# N575F145_v1 register map
File version: 1.0
Registers are 32-bit, read-write, reset 0x0 unless marked. A register's access mark holds for its fields unless they carry their own. Offsets are from the block's base; [hi:lo] are bit positions.

## UART0 — UART0 Register Map
Base 0x40050000
0x00 DATA reset not defined — UART0 Receive/Transfer FIFO Register.
  [7:0] _8_bitReceivedData — Receive FIFO Register. Reading this register will return data from the receive data FIFO. By reading this register, the UART will return the 8-bit data received from Rx pin (LSB first).
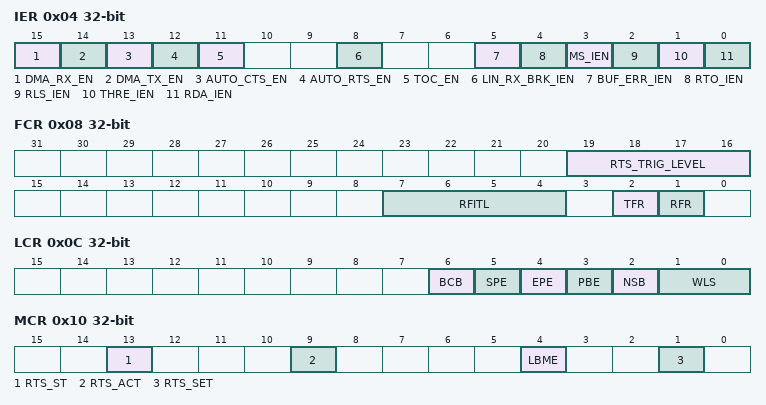
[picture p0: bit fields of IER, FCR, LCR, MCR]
0x04 IER — UART0 Interrupt Enable Register.
  [15] DMA_RX_EN — Receive DMA Enable. If enabled, the UART will request DMA service when data is available in receive FIFO.
  [14] DMA_TX_EN — Transmit DMA Enable. If enabled, the UART will request DMA service when space is available in transmit FIFO.
  [13] AUTO_CTS_EN — CTS Auto Flow Control Enable. When CTS auto-flow is enabled, the UART will send data to external device when CTS input is asserted (UART will not send data to device until CTS is asserted).
    0=Disable CTS auto flow control; 1=Enable
  [12] AUTO_RTS_EN — RTS Auto Flow Control Enable. When RTS auto-flow is enabled, if the number of bytes in the Rx FIFO equals FCR.RTS_TRIG_LEVEL, the UART will de-assert the RTS signal.
    0=Disable RTS auto flow control; 1=Enable
  [11] TOC_EN — Time-Out Counter Enable
    0=Disable Time-out counter; 1=Enable
  [8] LIN_RX_BRK_IEN — LIN RX Break Field Detected Interrupt Enable
    0=Mask off Lin bus Rx break field interrupt; 1=Enable Lin bus Rx break field interrupt
  [5] BUF_ERR_IEN — Buffer Error Interrupt Enable
    0=Mask off BUF_ERR_INT; 1=Enable IBUF_ERR_INT
  [4] RTO_IEN — Receive Time out Interrupt Enable
    0=Mask off TOUT_INT; 1=Enable TOUT_INT
  [3] MS_IEN — Modem Status Interrupt Enable
    0=Mask off MODEM_INT; 1=Enable MODEM_INT
  [2] RLS_IEN — Receive Line Status Interrupt Enable
    0=Mask off RLS_INT; 1=Enable RLS_INT
  [1] THRE_IEN — Transmit FIFO Register Empty Interrupt Enable
    0=Mask off THRE_INT; 1=Enable THRE_INT
  [0] RDA_IEN — Receive Data Available Interrupt Enable.
    0=Mask off RDA_INT; 1=Enable RDA_INT
0x08 FCR — UART0 FIFO Control Register.
  [19:16] RTS_TRIG_LEVEL — RTS Trigger Level for Auto-flow Control. Sets the FIFO trigger level when auto-flow control will de-assert RTS (request-to-send). Value : Trigger Level (Bytes). 0 : 1. 1 : 4. 2 : 8
  [7:4] RFITL — Receive FIFO Interrupt (RDA_INT) Trigger Level. When the number of bytes in the receive FIFO equals the RFITL then the RDA_IF will be set and, if enabled, an RDA_INT interrupt will generated. Value : INTR_RDA Trigger Level (Bytes). 0 : 1. 1 : 4. 2 : 8
  [2] TFR — Transmit FIFO Reset. When TFR is set, all the bytes in the transmit FIFO are cleared and transmit internal state machine is reset. Note: This bit will auto-clear after 3 UART engine clock cycles.
    0=Writing 0 to this bit has no effect; 1=Writing 1 to this bit will reset the transmit internal state machine and pointers
  [1] RFR — Receive FIFO Reset. When RFR is set, all the bytes in the receive FIFO are cleared and receive internal state machine is reset. Note: This bit will auto-clear after 3 UART engine clock cycles.
    0=Writing 0 to this bit has no effect; 1=Writing 1 to this bit will reset the receive internal state machine and pointers
0x0C LCR — UART0 Line Control Register.
  [6] BCB — Break Control Bit. When this bit is set to logic 1, the serial data output (Tx) is forced to the 'Space' state (logic 0). Normal condition is serial data output is 'Mark' state. This bit acts only on Tx and has no effect on the transmitter logic.
  [5] SPE — Stick Parity Enable
    0=Disable stick parity; 1=When bits PBE and SPE are set 'Stick Parity' is enabled. If EPE=0 the parity bit is transmitted and checked as always set, if EPE=1, the parity bit is transmitted and checked as always cleared
  [4] EPE — Even Parity Enable. This bit has effect only when PBE (parity bit enable) is set.
    0=Odd number of logic 1's are transmitted or checked in the data word and parity bits; 1=Even number of logic 1's are transmitted or checked in the data word and parity bits
  [3] PBE — Parity Bit Enable
    0=Parity bit is not generated (transmit data) or checked (receive data) during transfer; 1=Parity bit is generated or checked between the "last data word bit" and "stop bit" of the serial data
  [2] NSB — Number of STOP bits
    0=One "STOP bit" is generated after the transmitted data; 1=Two "STOP bits" are generated when 6-, 7- and 8-bit word length is selected; One and a half "STOP bits" are generated in the transmitted data when 5-bit word length is selected;
  [1:0] WLS — Word Length Select. 0 (5bits), 1(6bits), 2(7bits), 3(8bits)
0x10 MCR — UART0 Modem Control Register.
  [13] RTS_ST ro — RTS Pin State (read only). This bit is the pin status of RTS.
  [9] RTS_ACT — Request-to-Send (RTS) Active Trigger Level. This bit can change the RTS trigger level.
    0=RTS is active low level; 1=RTS is active high level
  [4] LBME — Loopback Mode Enable
    0=Disable; 1=Enable
  [1] RTS_SET — RTS (Request-To-Send) Signal. If IER.AUTO_RTS_EN = 0, this bit controls whether RTS pin is active or not.
    0=Drive RTS inactive ( = ~RTS_ACT); 1=Drive RTS active ( = RTS_ACT)
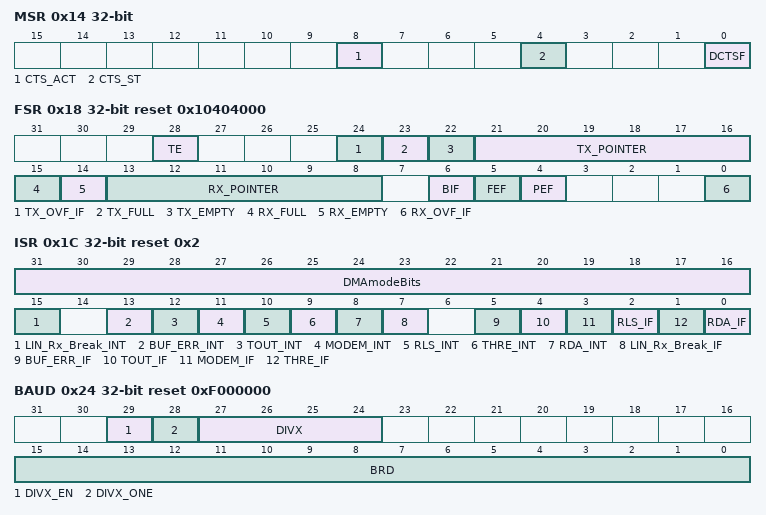
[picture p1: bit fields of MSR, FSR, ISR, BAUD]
0x14 MSR — UART0 Modem Status Register.
  [8] CTS_ACT — Clear-to-Send (CTS) Active Trigger Level. This bit can change the CTS trigger level.
    0=CTS is active low level; 1=CTS is active high level
  [4] CTS_ST ro — CTS Pin Status (read only). This bit is the pin status of CTS.
  [0] DCTSF — Detect CTS State Change Flag. This bit is set whenever CTS input has state change. It will generate Modem interrupt to CPU when IER.MS_IEN = 1. NOTE: This bit is cleared by writing 1 to itself.
0x18 FSR reset 0x10404000 — UART0 FIFO Status Register.
  [28] TE ro — Transmitter Empty (Read Only). Bit is set by hardware when Tx FIFO is empty and the STOP bit of the last byte has been transmitted. Bit is cleared automatically when Tx FIFO is not empty or the last byte transmission has not completed. NOTE: This bit is read only.
  [24] TX_OVF_IF — Tx Overflow Error Interrupt Flag. If the Tx FIFO (UART0->DATA) is full, an additional write to UART0->DATA will cause an overflow condition and set this bit to logic 1. It will also generate a BUF_ERR_IF event and interrupt if enabled. NOTE: This bit is cleared by writing 1 to itself.
  [23] TX_FULL ro — Transmit FIFO Full (Read Only). This bit indicates whether the Tx FIFO is full or not.
  [22] TX_EMPTY ro — Transmit FIFO Empty (Read Only). This bit indicates whether the Tx FIFO is empty or not. When the last byte of Tx FIFO has been transferred to Transmitter Shift Register, hardware sets this bit high. It will be cleared after writing data to FIFO (Tx FIFO not empty).
  [21:16] TX_POINTER ro — Tx FIFO Pointer (Read Only). This field returns the Tx FIFO buffer pointer. When CPU writes a byte into the Tx FIFO, TX_POINTER is incremented. When a byte from Tx FIFO is transferred to the Transmit Shift Register, TX_POINTER is decremented.
  [15] RX_FULL ro — Receive FIFO Full (Read Only). This bit indicates whether the Rx FIFO is full or not. This bit is set when Rx FIFO is full; otherwise it is cleared by hardware.
  [14] RX_EMPTY ro — Receive FIFO Empty (Read Only). This bit indicates whether the Rx FIFO is empty or not. When the last byte of Rx FIFO has been read by CPU, hardware sets this bit high. It will be cleared when UART receives any new data.
  [13:8] RX_POINTER ro — Rx FIFO pointer (Read Only). This field returns the Rx FIFO buffer pointer. It is the number of bytes available for read in the Rx FIFO. When UART receives one byte from external device, RX_POINTER is incremented. When one byte of Rx FIFO is read by CPU, RX_POINTER is decremented.
  [6] BIF — Break Interrupt Flag. This bit is set to a logic 1 whenever the receive data input (Rx) is held in the "space" state (logic 0) for longer than a full word transmission time (that is, the total time of start bit + data bits + parity + stop bits). It is reset whenever the CPU writes 1 to this bit.
  [5] FEF — Framing Error Flag. This bit is set to logic 1 whenever the received character does not have a valid "stop bit" (that is, the stop bit following the last data bit or parity bit is detected as a logic 0), and is reset whenever the CPU writes 1 to this bit.
  [4] PEF — Parity Error Flag. This bit is set to logic 1 whenever the received character does not have a valid "parity bit", and is reset whenever the CPU writes 1 to this bit.
  [0] RX_OVF_IF — Rx Overflow Error Interrupt Flag. If the Rx FIFO (UART0->DATA) is full, and an additional byte is received by the UART, an overflow condition will occur and set this bit to logic 1. It will also generate a BUF_ERR_IF event and interrupt if enabled. NOTE: This bit is cleared by writing 1 to itself.
0x1C ISR reset 0x2 — UART0 Interrupt Status Register.
  [31:16] DMAmodeBits — DMA Mode Bits. DMA mode equivalent following interrupt indicators and flags. See Table 5107 and normal mode descriptions below. In DMA mode (either DMA transmit or receive requests are active) these bits are generated rather than the normal use bits below.
  [15] LIN_Rx_Break_INT — LIN Bus Rx Break Field Detected Interrupt Indicator to Interrupt Controller. Logical AND of IER.LIN_RX_BRK_IEN and LIN_Rx_Break_IF.
  [13] BUF_ERR_INT — Buffer Error Interrupt Indicator to Interrupt Controller. Logical AND of IER.BUF_ERR_IEN and BUF_ERR_IF.
  [12] TOUT_INT — Time Out Interrupt Indicator to Interrupt Controller. Logical AND of IER.RTO_IEN and TOUT_IF.
  [11] MODEM_INT — MODEM Status Interrupt Indicator to Interrupt. Logical AND of IER.MS_IEN and MODEM_IF.
  [10] RLS_INT — Receive Line Status Interrupt Indicator to Interrupt Controller. Logical AND of IER.RLS_IEN and RLS_IF.
  [9] THRE_INT — Transmit Holding Register Empty Interrupt Indicator to Interrupt Controller. Logical AND of IER.THRE_IEN and THRE_IF.
  [8] RDA_INT — Receive Data Available Interrupt Indicator to Interrupt Controller. Logical AND of IER.RDA_IEN and RDA_IF.
  [7] LIN_Rx_Break_IF — LIN Bus Rx Break Field Detected Flag. This bit is set when LIN controller detects a break field. This bit is cleared by writing a 1.
  [5] BUF_ERR_IF ro — Buffer Error Interrupt Flag (Read Only). This bit is set when either the Tx or Rx FIFO overflows (FSR.TX_OVF_IF or FSR.RX_OVF_IF is set). When BUF_ERR_IF is set, the serial transfer may be corrupted. If IER.BUF_ERR_IEN is enabled a CPU interrupt request will be generated. NOTE: This bit is cleared when both FSR.TX_OVF_IF and FSR.RX_OVF_IF are cleared.
  [4] TOUT_IF ro — Time Out Interrupt Flag (Read Only). This bit is set when the Rx FIFO is not empty and no activity occurs in the Rx FIFO and the time out counter equal to TOIC. If IER.TOUT_IEN is enabled a CPU interrupt request will be generated. NOTE: This bit is read only and user can read FIFO to clear it.
  [3] MODEM_IF ro — MODEM Interrupt Flag (Read Only). NOTE: This bit is read only and reset when bit MSR.DCTSF is cleared by a write 1.
  [2] RLS_IF ro — Receive Line Status Interrupt Flag (Read Only). This bit is set when the Rx receive data has a parity, framing or break error (at least one of, FSR.BIF, FSR.FEF and FSR.PEF, is set). If IER.RLS_IEN is enabled, the RLS interrupt will be generated. NOTE: This bit is read only and reset to 0 when all bits of BIF, FEF and PEF are cleared.
  [1] THRE_IF ro — Transmit Holding Register Empty Interrupt Flag (Read Only). This bit is set when the last data of Tx FIFO is transferred to Transmitter Shift Register. If IER.THRE_IEN is enabled, the THRE interrupt will be generated. NOTE: This bit is read only and it will be cleared when writing data into the Tx FIFO.
  [0] RDA_IF ro — Receive Data Available Interrupt Flag (Read Only). When the number of bytes in the Rx FIFO equals FCR.RFITL then the RDA_IF will be set. If IER.RDA_IEN is enabled, the RDA interrupt will be generated. NOTE: This bit is read only and it will be cleared when the number of unread bytes of Rx FIFO drops below the threshold level (RFITL).
0x20 TOR — UART0 Time Out Register
  [6:0] TOIC — Time Out Interrupt Comparator. The time out counter resets and starts counting whenever the Rx FIFO receives a new data word. Once the content of time out counter (TOUT_CNT) is equal to that of time out interrupt comparator (TOIC), a receiver time out interrupt (TOUT_INT) is generated if IER.RTO_IEN is set. A new incoming data word or RX FIFO empty clears TOUT_IF. The period of the time out counter is the baud rate.
0x24 BAUD reset 0xF000000 — UART0 Baud Rate Divisor Register
  [29] DIVX_EN — Divider X Enable. The baud rate equation is: Baud Rate = UART_CLK / [ M * (BRD + 2) ] ; The default value of M is 16. Refer to Table 5111 for more information. NOTE: When in IrDA mode, this bit must disabled.
    0=Disable divider X ( M = 16); 1=Enable divider X (M = DIVX+1, with DIVX ≥ 8)
  [28] DIVX_ONE — Divider X equal 1. 0: M = DIVX+1, with restriction DIVX ≥ 8. 1: M = 1, with restriction BRD[15:0] ≥ 3. Refer to Table 5111 for more information.
  [27:24] DIVX — Divider X. The baud rate divider M = DIVX+1.
  [15:0] BRD — Baud Rate Divider. Refer to Table 5111 for more information.
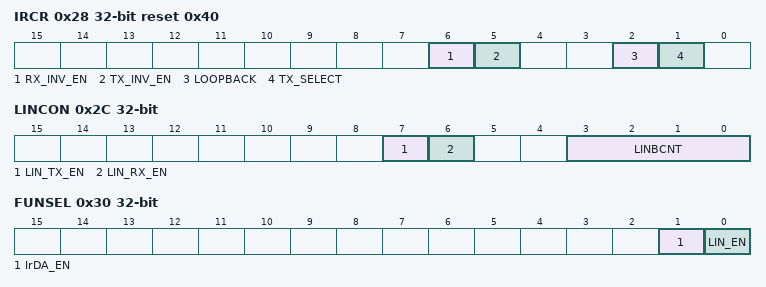
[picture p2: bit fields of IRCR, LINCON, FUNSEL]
0x28 IRCR reset 0x40 — UART0 IrDA Control Register.
  [6] RX_INV_EN — Receive Inversion Enable
    0=No inversion; 1=Invert Rx input signal
  [5] TX_INV_EN — Transmit inversion enable
    0=No inversion; 1=Invert Tx output signal
  [2] LOOPBACK — IrDA Loopback Test Mode. Loopback Tx to Rx.
  [1] TX_SELECT — Transmit/Receive Selection
    0=Enable IrDA receiver; 1=Enable IrDA transmitter
0x2C LINCON — UART0 LIN Control Register.
  [7] LIN_TX_EN — LIN TX Break Mode Enable. NOTE: When Tx break field transfer operation finished, this bit will be cleared automatically.
    0=Disable LIN Tx Break Mode; 1=Enable LIN Tx Break Mode
  [6] LIN_RX_EN — LIN RX Enable
    0=Disable LIN Rx mode; 1=Enable LIN Rx mode
  [3:0] LINBCNT — UART LIN Break Field Length Count. This field indicates a 4-bit LIN Tx break field count. NOTE: This break field length is LINBCNT + 2
0x30 FUNSEL — UART0 Function Select Register.
  [1] IrDA_EN — Enable IrDA Function
    0=UART Function; 1=Enable IrDA Function
  [0] LIN_EN — Enable LIN Function. Note that IrDA and LIN functions are mutually exclusive: both cannot be active at same time.
    0=UART Function; 1=Enable LIN Function
